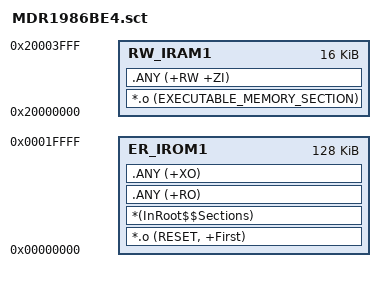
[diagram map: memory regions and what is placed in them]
; ******************************************************************************
; ************* Scatter-Loading Description File for MDR1986BE4 ****************
; ******************************************************************************

LR_IROM1 0x00000000 0x00020000  {      ; load region size_region
    ER_IROM1 0x00000000 0x00020000  {  ; load address = execution address
        *.o (RESET, +First)
        *(InRoot$$Sections)
        .ANY (+RO)
        .ANY (+XO)
    }
    RW_IRAM1 0x20000000 0x00004000  {  ; RW data
        *.o (EXECUTABLE_MEMORY_SECTION)
        .ANY (+RW +ZI)
    }
}

